# ESP32-C3 register map
Vendor: ESPRESSIF SYSTEMS (SHANGHAI) CO., LTD.; Series: ESP32 C-Series; File version: 18
CPU: RV32IMC r0p0, little endian, no MPU, no FPU, 0 interrupt priority bits
Address unit: 32 bits
Registers are 32-bit, read-write, reset 0x0 unless marked. A register's access mark holds for its fields unless they carry their own. Offsets are from the block's base; [hi:lo] are bit positions; {n}, {i} and the like mark numbered series.

## SYSTEM — System Configuration Registers
Base 0x600C0000
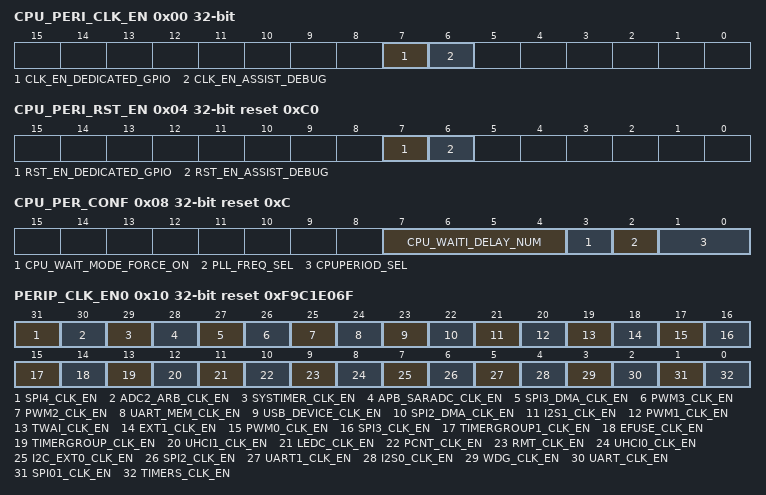
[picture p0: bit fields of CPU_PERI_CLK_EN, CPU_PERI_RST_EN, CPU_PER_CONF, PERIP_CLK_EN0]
0x00 CPU_PERI_CLK_EN — cpu_peripheral clock gating register
  [7] CLK_EN_DEDICATED_GPIO — reg_clk_en_dedicated_gpio
  [6] CLK_EN_ASSIST_DEBUG — reg_clk_en_assist_debug
0x04 CPU_PERI_RST_EN reset 0xC0 — cpu_peripheral reset register
  [7] RST_EN_DEDICATED_GPIO — reg_rst_en_dedicated_gpio
  [6] RST_EN_ASSIST_DEBUG — reg_rst_en_assist_debug
0x08 CPU_PER_CONF reset 0xC — cpu clock config register
  [7:4] CPU_WAITI_DELAY_NUM — reg_cpu_waiti_delay_num
  [3] CPU_WAIT_MODE_FORCE_ON — reg_cpu_wait_mode_force_on
  [2] PLL_FREQ_SEL — reg_pll_freq_sel
  [1:0] CPUPERIOD_SEL — reg_cpuperiod_sel
0x0C MEM_PD_MASK reset 0x1 — memory power down mask register
  [0] LSLP_MEM_PD_MASK — reg_lslp_mem_pd_mask
0x10 PERIP_CLK_EN0 reset 0xF9C1E06F — peripheral clock gating register
  [31] SPI4_CLK_EN — reg_spi4_clk_en
  [30] ADC2_ARB_CLK_EN — reg_adc2_arb_clk_en
  [29] SYSTIMER_CLK_EN — reg_systimer_clk_en
  [28] APB_SARADC_CLK_EN — reg_apb_saradc_clk_en
  [27] SPI3_DMA_CLK_EN — reg_spi3_dma_clk_en
  [26] PWM3_CLK_EN — reg_pwm3_clk_en
  [25] PWM2_CLK_EN — reg_pwm2_clk_en
  [24] UART_MEM_CLK_EN — reg_uart_mem_clk_en
  [23] USB_DEVICE_CLK_EN — reg_usb_device_clk_en
  [22] SPI2_DMA_CLK_EN — reg_spi2_dma_clk_en
  [21] I2S1_CLK_EN — reg_i2s1_clk_en
  [20] PWM1_CLK_EN — reg_pwm1_clk_en
  [19] TWAI_CLK_EN — reg_can_clk_en
  [18] EXT1_CLK_EN — reg_ext1_clk_en
  [17] PWM0_CLK_EN — reg_pwm0_clk_en
  [16] SPI3_CLK_EN — reg_spi3_clk_en
  [15] TIMERGROUP1_CLK_EN — reg_timergroup1_clk_en
  [14] EFUSE_CLK_EN — reg_efuse_clk_en
  [13] TIMERGROUP_CLK_EN — reg_timergroup_clk_en
  [12] UHCI1_CLK_EN — reg_uhci1_clk_en
  [11] LEDC_CLK_EN — reg_ledc_clk_en
  [10] PCNT_CLK_EN — reg_pcnt_clk_en
  [9] RMT_CLK_EN — reg_rmt_clk_en
  [8] UHCI0_CLK_EN — reg_uhci0_clk_en
  [7] I2C_EXT0_CLK_EN — reg_ext0_clk_en
  [6] SPI2_CLK_EN — reg_spi2_clk_en
  [5] UART1_CLK_EN — reg_uart1_clk_en
  [4] I2S0_CLK_EN — reg_i2s0_clk_en
  [3] WDG_CLK_EN — reg_wdg_clk_en
  [2] UART_CLK_EN — reg_uart_clk_en
  [1] SPI01_CLK_EN — reg_spi01_clk_en
  [0] TIMERS_CLK_EN — reg_timers_clk_en
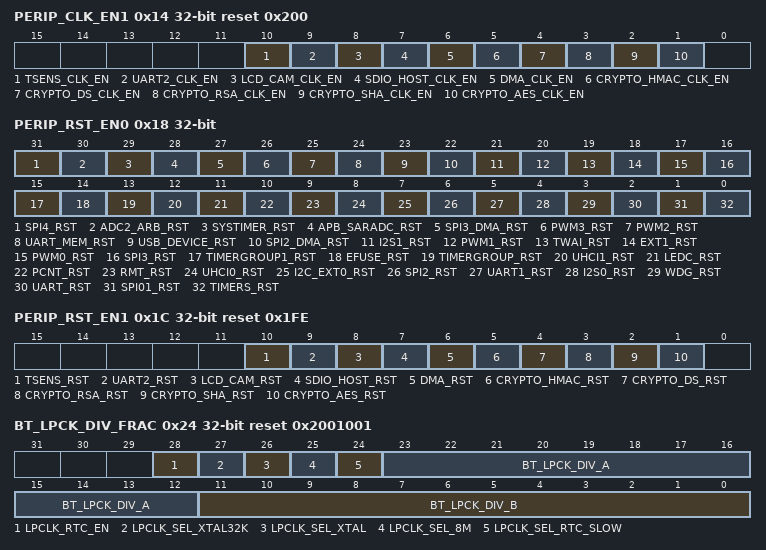
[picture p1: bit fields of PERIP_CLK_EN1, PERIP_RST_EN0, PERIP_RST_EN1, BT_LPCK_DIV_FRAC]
0x14 PERIP_CLK_EN1 reset 0x200 — peripheral clock gating register
  [10] TSENS_CLK_EN — reg_tsens_clk_en
  [9] UART2_CLK_EN — reg_uart2_clk_en
  [8] LCD_CAM_CLK_EN — reg_lcd_cam_clk_en
  [7] SDIO_HOST_CLK_EN — reg_sdio_host_clk_en
  [6] DMA_CLK_EN — reg_dma_clk_en
  [5] CRYPTO_HMAC_CLK_EN — reg_crypto_hmac_clk_en
  [4] CRYPTO_DS_CLK_EN — reg_crypto_ds_clk_en
  [3] CRYPTO_RSA_CLK_EN — reg_crypto_rsa_clk_en
  [2] CRYPTO_SHA_CLK_EN — reg_crypto_sha_clk_en
  [1] CRYPTO_AES_CLK_EN — reg_crypto_aes_clk_en
0x18 PERIP_RST_EN0 — reserved
  [31] SPI4_RST — reg_spi4_rst
  [30] ADC2_ARB_RST — reg_adc2_arb_rst
  [29] SYSTIMER_RST — reg_systimer_rst
  [28] APB_SARADC_RST — reg_apb_saradc_rst
  [27] SPI3_DMA_RST — reg_spi3_dma_rst
  [26] PWM3_RST — reg_pwm3_rst
  [25] PWM2_RST — reg_pwm2_rst
  [24] UART_MEM_RST — reg_uart_mem_rst
  [23] USB_DEVICE_RST — reg_usb_device_rst
  [22] SPI2_DMA_RST — reg_spi2_dma_rst
  [21] I2S1_RST — reg_i2s1_rst
  [20] PWM1_RST — reg_pwm1_rst
  [19] TWAI_RST — reg_can_rst
  [18] EXT1_RST — reg_ext1_rst
  [17] PWM0_RST — reg_pwm0_rst
  [16] SPI3_RST — reg_spi3_rst
  [15] TIMERGROUP1_RST — reg_timergroup1_rst
  [14] EFUSE_RST — reg_efuse_rst
  [13] TIMERGROUP_RST — reg_timergroup_rst
  [12] UHCI1_RST — reg_uhci1_rst
  [11] LEDC_RST — reg_ledc_rst
  [10] PCNT_RST — reg_pcnt_rst
  [9] RMT_RST — reg_rmt_rst
  [8] UHCI0_RST — reg_uhci0_rst
  [7] I2C_EXT0_RST — reg_ext0_rst
  [6] SPI2_RST — reg_spi2_rst
  [5] UART1_RST — reg_uart1_rst
  [4] I2S0_RST — reg_i2s0_rst
  [3] WDG_RST — reg_wdg_rst
  [2] UART_RST — reg_uart_rst
  [1] SPI01_RST — reg_spi01_rst
  [0] TIMERS_RST — reg_timers_rst
0x1C PERIP_RST_EN1 reset 0x1FE — peripheral reset register
  [10] TSENS_RST — reg_tsens_rst
  [9] UART2_RST — reg_uart2_rst
  [8] LCD_CAM_RST — reg_lcd_cam_rst
  [7] SDIO_HOST_RST — reg_sdio_host_rst
  [6] DMA_RST — reg_dma_rst
  [5] CRYPTO_HMAC_RST — reg_crypto_hmac_rst
  [4] CRYPTO_DS_RST — reg_crypto_ds_rst
  [3] CRYPTO_RSA_RST — reg_crypto_rsa_rst
  [2] CRYPTO_SHA_RST — reg_crypto_sha_rst
  [1] CRYPTO_AES_RST — reg_crypto_aes_rst
0x20 BT_LPCK_DIV_INT reset 0xFF — clock config register
  [11:0] BT_LPCK_DIV_NUM — reg_bt_lpck_div_num
0x24 BT_LPCK_DIV_FRAC reset 0x2001001 — clock config register
  [28] LPCLK_RTC_EN — reg_lpclk_rtc_en
  [27] LPCLK_SEL_XTAL32K — reg_lpclk_sel_xtal32k
  [26] LPCLK_SEL_XTAL — reg_lpclk_sel_xtal
  [25] LPCLK_SEL_8M — reg_lpclk_sel_8m
  [24] LPCLK_SEL_RTC_SLOW — reg_lpclk_sel_rtc_slow
  [23:12] BT_LPCK_DIV_A — reg_bt_lpck_div_a
  [11:0] BT_LPCK_DIV_B — reg_bt_lpck_div_b
{0x28+4i} CPU_INTR_FROM_CPU_{i} (i=0..3) — interrupt generate register
  [0] CPU_INTR_FROM_CPU_{i} — reg_cpu_intr_from_cpu_{i}
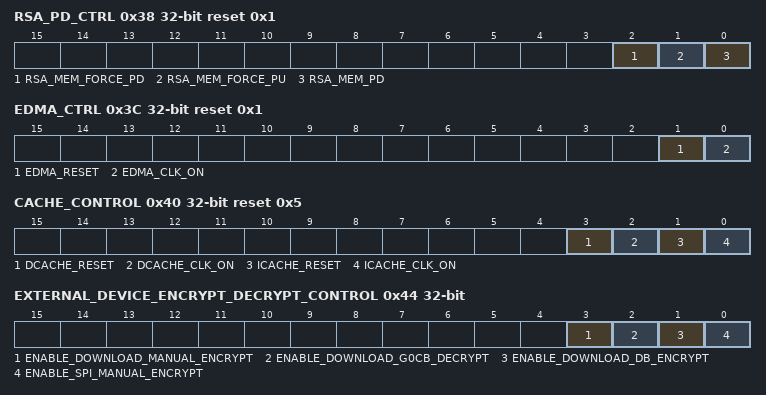
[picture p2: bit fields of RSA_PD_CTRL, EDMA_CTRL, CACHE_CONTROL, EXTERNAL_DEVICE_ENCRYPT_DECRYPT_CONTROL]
0x38 RSA_PD_CTRL reset 0x1 — rsa memory power control register
  [2] RSA_MEM_FORCE_PD — reg_rsa_mem_force_pd
  [1] RSA_MEM_FORCE_PU — reg_rsa_mem_force_pu
  [0] RSA_MEM_PD — reg_rsa_mem_pd
0x3C EDMA_CTRL reset 0x1 — EDMA clock and reset register
  [1] EDMA_RESET — reg_edma_reset
  [0] EDMA_CLK_ON — reg_edma_clk_on
0x40 CACHE_CONTROL reset 0x5
  [3] DCACHE_RESET — reg_dcache_reset
  [2] DCACHE_CLK_ON — reg_dcache_clk_on
  [1] ICACHE_RESET — reg_icache_reset
  [0] ICACHE_CLK_ON — reg_icache_clk_on
0x44 EXTERNAL_DEVICE_ENCRYPT_DECRYPT_CONTROL — SYSTEM_EXTERNAL_DEVICE_ENCRYPT_DECRYPT_CONTROL_REG
  [3] ENABLE_DOWNLOAD_MANUAL_ENCRYPT — reg_enable_download_manual_encrypt
  [2] ENABLE_DOWNLOAD_G0CB_DECRYPT — reg_enable_download_g0cb_decrypt
  [1] ENABLE_DOWNLOAD_DB_ENCRYPT — reg_enable_download_db_encrypt
  [0] ENABLE_SPI_MANUAL_ENCRYPT — reg_enable_spi_manual_encrypt
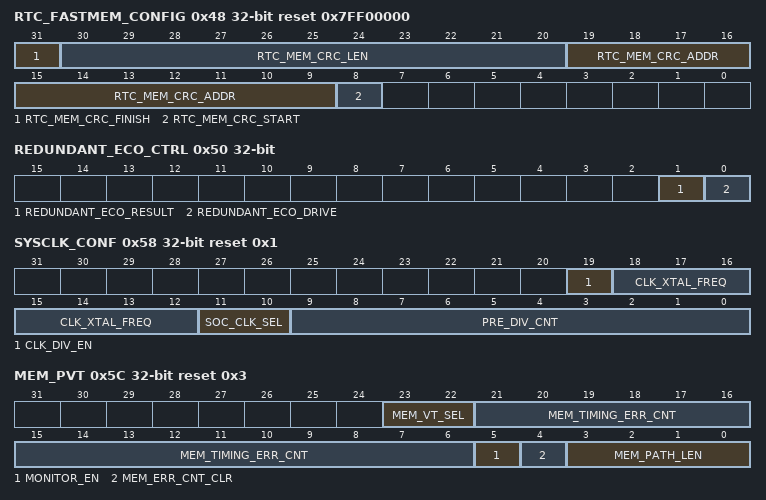
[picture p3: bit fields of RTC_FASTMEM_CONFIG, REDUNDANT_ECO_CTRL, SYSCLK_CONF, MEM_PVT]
0x48 RTC_FASTMEM_CONFIG access per field reset 0x7FF00000 — fast memory config register
  [31] RTC_MEM_CRC_FINISH ro — reg_rtc_mem_crc_finish
  [30:20] RTC_MEM_CRC_LEN rw — reg_rtc_mem_crc_len
  [19:9] RTC_MEM_CRC_ADDR rw — reg_rtc_mem_crc_addr
  [8] RTC_MEM_CRC_START rw — reg_rtc_mem_crc_start
0x4C RTC_FASTMEM_CRC ro — reserved
  [31:0] RTC_MEM_CRC_RES — reg_rtc_mem_crc_res
0x50 REDUNDANT_ECO_CTRL access per field — eco register
  [1] REDUNDANT_ECO_RESULT ro — reg_redundant_eco_result
  [0] REDUNDANT_ECO_DRIVE rw — reg_redundant_eco_drive
0x54 CLOCK_GATE reset 0x1 — clock gating register
  [0] CLK_EN — reg_clk_en
0x58 SYSCLK_CONF access per field reset 0x1 — system clock config register
  [19] CLK_DIV_EN ro — reg_clk_div_en
  [18:12] CLK_XTAL_FREQ ro — reg_clk_xtal_freq
  [11:10] SOC_CLK_SEL rw — reg_soc_clk_sel
  [9:0] PRE_DIV_CNT rw — reg_pre_div_cnt
0x5C MEM_PVT access per field reset 0x3
  [23:22] MEM_VT_SEL rw — reg_mem_vt_sel
  [21:6] MEM_TIMING_ERR_CNT ro — reg_mem_timing_err_cnt
  [5] MONITOR_EN rw — reg_mem_pvt_monitor_en
  [4] MEM_ERR_CNT_CLR wo — reg_mem_err_cnt_clr
  [3:0] MEM_PATH_LEN rw — reg_mem_path_len
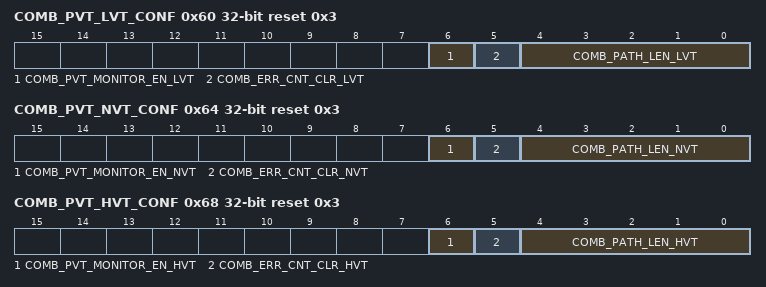
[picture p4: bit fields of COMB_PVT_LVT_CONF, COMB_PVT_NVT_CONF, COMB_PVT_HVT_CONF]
0x60 COMB_PVT_LVT_CONF access per field reset 0x3 — mem pvt register
  [6] COMB_PVT_MONITOR_EN_LVT rw — reg_comb_pvt_monitor_en_lvt
  [5] COMB_ERR_CNT_CLR_LVT wo — reg_comb_err_cnt_clr_lvt
  [4:0] COMB_PATH_LEN_LVT rw — reg_comb_path_len_lvt
0x64 COMB_PVT_NVT_CONF access per field reset 0x3 — mem pvt register
  [6] COMB_PVT_MONITOR_EN_NVT rw — reg_comb_pvt_monitor_en_nvt
  [5] COMB_ERR_CNT_CLR_NVT wo — reg_comb_err_cnt_clr_nvt
  [4:0] COMB_PATH_LEN_NVT rw — reg_comb_path_len_nvt
0x68 COMB_PVT_HVT_CONF access per field reset 0x3 — mem pvt register
  [6] COMB_PVT_MONITOR_EN_HVT rw — reg_comb_pvt_monitor_en_hvt
  [5] COMB_ERR_CNT_CLR_HVT wo — reg_comb_err_cnt_clr_hvt
  [4:0] COMB_PATH_LEN_HVT rw — reg_comb_path_len_hvt
{0x6C+0xC*i} COMB_PVT_ERR_LVT_SITE{i} ro (i=0..3) — mem pvt register
  [15:0] COMB_TIMING_ERR_CNT_LVT_SITE{i} — reg_comb_timing_err_cnt_lvt_site{i}
{0x70+0xC*i} COMB_PVT_ERR_NVT_SITE{i} ro (i=0..3) — mem pvt register
  [15:0] COMB_TIMING_ERR_CNT_NVT_SITE{i} — reg_comb_timing_err_cnt_nvt_site{i}
{0x74+0xC*i} COMB_PVT_ERR_HVT_SITE{i} ro (i=0..3) — mem pvt register
  [15:0] COMB_TIMING_ERR_CNT_HVT_SITE{i} — reg_comb_timing_err_cnt_hvt_site{i}
0xFFC SYSTEM_REG_DATE reset 0x2007150 — Version register
  [27:0] SYSTEM_REG_DATE — reg_system_reg_date
